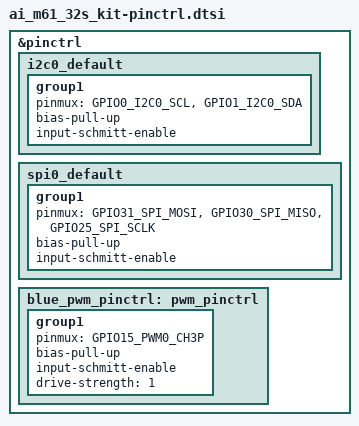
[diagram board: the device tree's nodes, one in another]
/*
 * Copyright (c) 2025-2026 MASSDRIVER EI (massdriver.space)
 *
 * SPDX-License-Identifier: Apache-2.0
 */

&pinctrl {
	i2c0_default: i2c0_default {
		group1 {
			pinmux = <GPIO0_I2C0_SCL>,
				 <GPIO1_I2C0_SDA>;
			bias-pull-up;
			input-schmitt-enable;
		};
	};

	spi0_default: spi0_default {
		group1 {
			pinmux = <GPIO31_SPI_MOSI>,
				 <GPIO30_SPI_MISO>,
				 <GPIO25_SPI_SCLK>;
			bias-pull-up;
			input-schmitt-enable;
		};
	};

	blue_pwm_pinctrl: pwm_pinctrl {
		group1 {
			pinmux = <GPIO15_PWM0_CH3P>;
			bias-pull-up;
			input-schmitt-enable;
			drive-strength = <1>;
		};
	};
};
